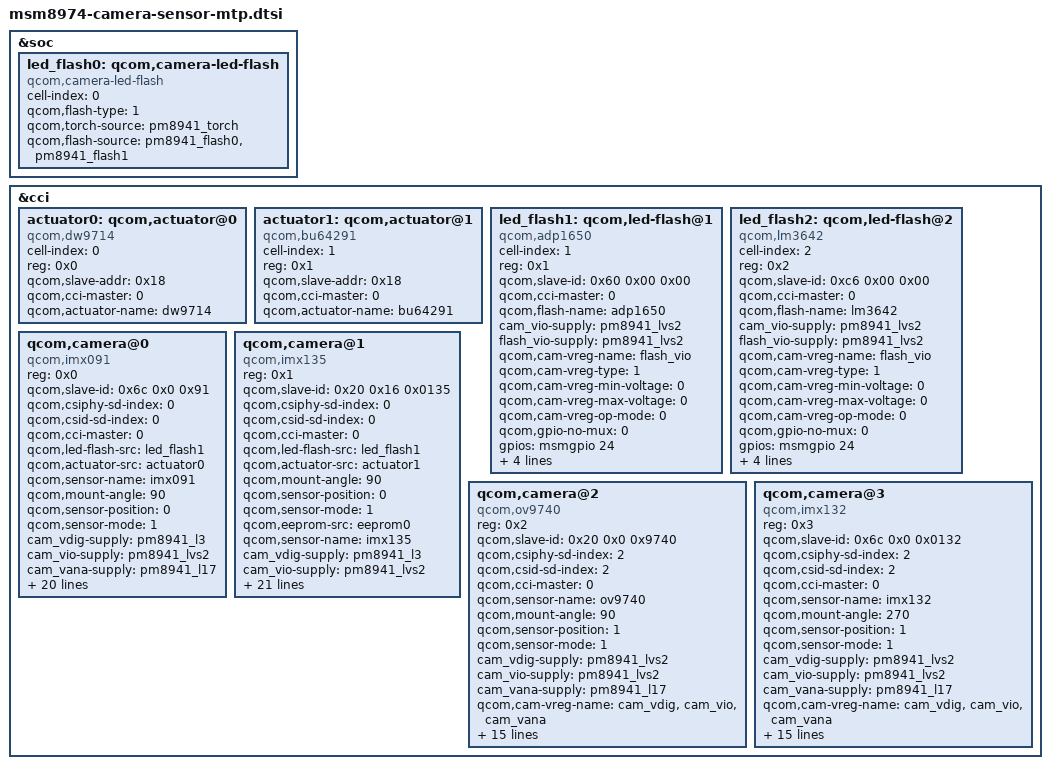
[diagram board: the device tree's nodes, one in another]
/*
 * Copyright (c) 2012-2013, The Linux Foundation. All rights reserved.
 *
 * This program is free software; you can redistribute it and/or modify
 * it under the terms of the GNU General Public License version 2 and
 * only version 2 as published by the Free Software Foundation.
 *
 * This program is distributed in the hope that it will be useful,
 * but WITHOUT ANY WARRANTY; without even the implied warranty of
 * MERCHANTABILITY or FITNESS FOR A PARTICULAR PURPOSE.  See the
 * GNU General Public License for more details.
 */

&soc {
	led_flash0: qcom,camera-led-flash {
		cell-index = <0>;
		compatible = "qcom,camera-led-flash";
		qcom,flash-type = <1>;
		qcom,torch-source = <&pm8941_torch>;
		qcom,flash-source = <&pm8941_flash0 &pm8941_flash1>;
	};
};

&cci {

/*
 * Commented by ZTE_JIA_20130419 jia.jia
 */
/*
	actuator0: qcom,actuator@18 {
		cell-index = <0>;
		reg = <0x18>;
		compatible = "qcom,actuator";
		qcom,cci-master = <0>;
	};

	actuator1: qcom,actuator@36 {
		cell-index = <1>;
		reg = <0x36>;
		compatible = "qcom,actuator";
		qcom,cci-master = <0>;
	};

	qcom,camera@6e {
		compatible = "qcom,s5k3l1yx";
		reg = <0x6e>;
		qcom,slave-id = <0x6e 0x0 0x3121>;
		qcom,csiphy-sd-index = <0>;
		qcom,csid-sd-index = <0>;
		qcom,actuator-src = <&actuator0>;
		qcom,led-flash-src = <&led_flash0>;
		qcom,mount-angle = <90>;
		qcom,sensor-name = "s5k3l1yx";
		cam_vdig-supply = <&pm8941_l3>;
		cam_vana-supply = <&pm8941_l17>;
		cam_vio-supply = <&pm8941_lvs3>;
		cam_vaf-supply = <&pm8941_l23>;
		qcom,cam-vreg-name = "cam_vdig", "cam_vio", "cam_vana",
				     "cam_vaf";
		qcom,cam-vreg-type = <0 1 0 0>;
		qcom,cam-vreg-min-voltage = <1225000 0 2850000 3000000>;
		qcom,cam-vreg-max-voltage = <1225000 0 2850000 3000000>;
		qcom,cam-vreg-op-mode = <105000 0 80000 100000>;
		qcom,gpio-no-mux = <0>;
		gpios = <&msmgpio 15 0>,
			<&msmgpio 90 0>,
			<&msmgpio 89 0>;
		qcom,gpio-reset = <1>;
		qcom,gpio-standby = <2>;
		qcom,gpio-req-tbl-num = <0 1 2>;
		qcom,gpio-req-tbl-flags = <1 0 0>;
		qcom,gpio-req-tbl-label = "CAMIF_MCLK",
					  "CAM_RESET1",
					  "CAM_STANDBY";
		qcom,gpio-set-tbl-num = <1 1>;
		qcom,gpio-set-tbl-flags = <0 2>;
		qcom,gpio-set-tbl-delay = <1000 30000>;
		qcom,csi-lane-assign = <0x4320>;
		qcom,csi-lane-mask = <0x1F>;
		qcom,sensor-position = <0>;
		qcom,sensor-mode = <1>;
		qcom,cci-master = <0>;
		status = "ok";
	};

    qcom,camera@20 {
		compatible = "qcom,imx135";
		reg = <0x20>;
		qcom,slave-id = <0x20 0x0016 0x0135>;
		qcom,csiphy-sd-index = <0>;
		qcom,csid-sd-index = <0>;
		qcom,mount-angle = <90>;
		qcom,sensor-name = "imx135";
		qcom,actuator-src = <&actuator1>;
		qcom,led-flash-src = <&led_flash0>;
		cam_vdig-supply = <&pm8941_l3>;
		cam_vana-supply = <&pm8941_l17>;
		cam_vio-supply = <&pm8941_lvs3>;
		cam_vaf-supply = <&pm8941_l23>;
		qcom,cam-vreg-name = "cam_vdig", "cam_vio", "cam_vana",
				     "cam_vaf";
		qcom,cam-vreg-type = <0 1 0 0>;
		qcom,cam-vreg-min-voltage = <1225000 0 2850000 3000000>;
		qcom,cam-vreg-max-voltage = <1225000 0 2850000 3000000>;
		qcom,cam-vreg-op-mode = <105000 0 80000 100000>;
		qcom,gpio-no-mux = <0>;
		gpios = <&msmgpio 15 0>,
			<&msmgpio 90 0>,
			<&msmgpio 89 0>;
		qcom,gpio-reset = <1>;
		qcom,gpio-standby = <2>;
		qcom,gpio-req-tbl-num = <0 1 2>;
		qcom,gpio-req-tbl-flags = <1 0 0>;
		qcom,gpio-req-tbl-label = "CAMIF_MCLK",
					  "CAM_RESET1",
					  "CAM_STANDBY";
		qcom,gpio-set-tbl-num = <1 1>;
		qcom,gpio-set-tbl-flags = <0 2>;
		qcom,gpio-set-tbl-delay = <1000 30000>;
		qcom,csi-lane-assign = <0x4320>;
		qcom,csi-lane-mask = <0x1F>;
		qcom,sensor-position = <0>;
		qcom,sensor-mode = <0>;
	        qcom,sensor-type = <0>;
		qcom,cci-master = <0>;
		status = "ok";
	};


	qcom,camera@6c {
		compatible = "qcom,ov2720";
		reg = <0x6c>;
		qcom,slave-id = <0x6c 0x300A 0x2720>;
		qcom,csiphy-sd-index = <2>;
		qcom,csid-sd-index = <2>;
		qcom,mount-angle = <90>;
		qcom,sensor-name = "ov2720";
		cam_vdig-supply = <&pm8941_l3>;
		cam_vana-supply = <&pm8941_l17>;
		cam_vio-supply = <&pm8941_lvs3>;
		qcom,cam-vreg-name = "cam_vdig", "cam_vana", "cam_vio";
		qcom,cam-vreg-type = <0 0 1>;
		qcom,cam-vreg-min-voltage = <1225000 2850000 0>;
		qcom,cam-vreg-max-voltage = <1225000 2850000 0>;
		qcom,cam-vreg-op-mode = <105000 80000 0>;
		qcom,gpio-no-mux = <0>;
		gpios = <&msmgpio 17 0>,
			<&msmgpio 18 0>;
		qcom,gpio-reset = <1>;
		qcom,gpio-req-tbl-num = <0 1>;
		qcom,gpio-req-tbl-flags = <1 0>;
		qcom,gpio-req-tbl-label = "CAMIF_MCLK",
					  "CAM_RESET1";
		qcom,gpio-set-tbl-num = <1 1>;
		qcom,gpio-set-tbl-flags = <0 2>;
		qcom,gpio-set-tbl-delay = <1000 4000>;
		qcom,csi-lane-assign = <0x4320>;
		qcom,csi-lane-mask = <0x7>;
		qcom,sensor-position = <1>;
		qcom,sensor-mode = <1>;
		qcom,cci-master = <1>;
		status = "ok";
	};

	qcom,camera@90 {
		compatible = "qcom,mt9m114";
		reg = <0x90>;
		qcom,slave-id = <0x90 0x0 0x2481>;
		qcom,csiphy-sd-index = <1>;
		qcom,csid-sd-index = <0>;
		qcom,mount-angle = <0>;
		qcom,sensor-name = "mt9m114";
		cam_vdig-supply = <&pm8941_l3>;
		cam_vana-supply = <&pm8941_l17>;
		cam_vio-supply = <&pm8941_lvs3>;
		qcom,cam-vreg-name = "cam_vdig", "cam_vana", "cam_vio";
		qcom,cam-vreg-type = <0 0 1>;
		qcom,cam-vreg-min-voltage = <1225000 2850000 0>;
		qcom,cam-vreg-max-voltage = <1225000 2850000 0>;
		qcom,cam-vreg-op-mode = <105000 80000 0>;
		qcom,gpio-no-mux = <0>;
		gpios = <&msmgpio 16 0>,
			<&msmgpio 92 0>;
		qcom,gpio-reset = <1>;
		qcom,gpio-req-tbl-num = <0 1>;
		qcom,gpio-req-tbl-flags = <1 0>;
		qcom,gpio-req-tbl-label = "CAMIF_MCLK",
					  "CAM_RESET1";
		qcom,gpio-set-tbl-num = <1 1>;
		qcom,gpio-set-tbl-flags = <0 2>;
		qcom,gpio-set-tbl-delay = <1000 4000>;
		qcom,csi-lane-assign = <0x4320>;
		qcom,csi-lane-mask = <0x3>;
		qcom,sensor-position = <1>;
		qcom,sensor-mode = <1>;
		qcom,cci-master = <0>;
	};
*/

/*
 * Common configuration of camera sensor & flash by ZTE_JIA_20130925, jia.jia
 *
 * See: arch/arm/boot/dts/msm8974-camera.dtsi
 *      arch/arm/boot/dts/msm8974-camera-sensor-mtp.dtsi
 *      arch/arm/boot/dts/msm8974-camera-sensor-mtp-avon.dtsi
 *      arch/arm/boot/dts/msm8974pro-ab-camera-sensor-mtp-barron.dtsi
 *      arch/arm/boot/dts/msm8974pro-ac-camera-sensor-mtp-barron.dtsi
 *      arch/arm/boot/dts/msm8974pro-ab-camera-sensor-mtp-chovar.dtsi
 */
// --->
	/*
	 * Support for Dongwoon dw9714
	 */
	actuator0: qcom,actuator@0 {
		cell-index = <0>;
		reg = <0x0>;
		qcom,slave-addr = <0x18>;
		compatible = "qcom,dw9714";
		qcom,cci-master = <0>;
		qcom,actuator-name = "dw9714";
	};

	/*
	 * Support for Rohm bu64291
	 */
	actuator1: qcom,actuator@1 {
		cell-index = <1>;
		reg = <0x1>;
		qcom,slave-addr = <0x18>;
		compatible = "qcom,bu64291";
		qcom,cci-master = <0>;
		qcom,actuator-name = "bu64291";
	};

	/*
	 * Support for AD adp1650
	 */
	led_flash1: qcom,led-flash@1 {
		cell-index = <1>;
		reg = <0x1>;
		qcom,slave-id = <0x60 0x00 0x00>;
		compatible = "qcom,adp1650";
		qcom,cci-master = <0>;
		qcom,flash-name = "adp1650";

		/*
		 * VDD configuration
		 *
		 * Refer to: kernel/include/media/msm_cam_sensor.h
		 * enum msm_camera_vreg_name_t {
		 *   CAM_VDIG,
		 *   CAM_VIO,
		 *   CAM_VANA,
		 *   CAM_VAF,
		 *   CAM_VREG_MAX,
		 * };
		 * Attention: index of qcom,cam-vreg-* MUST be as same as that of 'msm_camera_vreg_name_t'
		 *
		 * enum camera_vreg_type {
		 *   REG_LDO,
		 *   REG_VS,
		 *   REG_GPIO,
		 * };
		 * Attention: 'min-voltage'/'max-voltage'/'op-mode' only required by ''REG_LDO'
		 */
		cam_vio-supply = <&pm8941_lvs2>;
		flash_vio-supply = <&pm8941_lvs2>;
		qcom,cam-vreg-name = "flash_vio";
		qcom,cam-vreg-type = <1>;
		qcom,cam-vreg-min-voltage = <0>;
		qcom,cam-vreg-max-voltage = <0>;
		qcom,cam-vreg-op-mode = <0>;

		/*
		 * GPIO configuration
		 */
		qcom,gpio-no-mux = <0>;
		gpios = <&msmgpio 24 0>;
		qcom,gpio-strobe = <0>;
		qcom,gpio-req-tbl-num = <0>;

		/* 0: output gpio, 1: input gpio */
		qcom,gpio-req-tbl-flags = <0>;

		qcom,gpio-req-tbl-label = "FLASH_STROBE";

		status = "ok";
	};

	/*
	 * Support for TI lm3642
	 */
	led_flash2: qcom,led-flash@2 {
		cell-index = <2>;
		reg = <0x2>;
		qcom,slave-id = <0xc6 0x00 0x00>;
		compatible = "qcom,lm3642";
		qcom,cci-master = <0>;
		qcom,flash-name = "lm3642";

		/*
		 * VDD configuration
		 *
		 * Refer to: kernel/include/media/msm_cam_sensor.h
		 * enum msm_camera_vreg_name_t {
		 *   CAM_VDIG,
		 *   CAM_VIO,
		 *   CAM_VANA,
		 *   CAM_VAF,
		 *   CAM_VREG_MAX,
		 * };
		 * Attention: index of qcom,cam-vreg-* MUST be as same as that of 'msm_camera_vreg_name_t'
		 *
		 * enum camera_vreg_type {
		 *   REG_LDO,
		 *   REG_VS,
		 *   REG_GPIO,
		 * };
		 * Attention: 'min-voltage'/'max-voltage'/'op-mode' only required by ''REG_LDO'
		 */
		cam_vio-supply = <&pm8941_lvs2>;
		flash_vio-supply = <&pm8941_lvs2>;
		qcom,cam-vreg-name = "flash_vio";
		qcom,cam-vreg-type = <1>;
		qcom,cam-vreg-min-voltage = <0>;
		qcom,cam-vreg-max-voltage = <0>;
		qcom,cam-vreg-op-mode = <0>;

		/*
		 * GPIO configuration
		 */
		qcom,gpio-no-mux = <0>;
		gpios = <&msmgpio 24 0>;
		qcom,gpio-strobe = <0>;
		qcom,gpio-req-tbl-num = <0>;

		/* 0: output gpio, 1: input gpio */
		qcom,gpio-req-tbl-flags = <0>;

		qcom,gpio-req-tbl-label = "FLASH_STROBE";

		status = "ok";
	};

	/*
	 * Support for Sony imx091 13Mp
	 *
	 * 'qcom,camera@X' & 'reg = <0xX>': index of camera sensor for mclk
	 * refer to kernel/arch/arm/mach-msm/clock-8974.c
	 *
	 * 'qcom,csid-sd-index' should be set as same as 'qcom,csiphy-sd-index'
	 * for rear/front camera, otherwise 'csid_open' will return error.
	 */
	qcom,camera@0 {
		compatible = "qcom,imx091";
		reg = <0x0>;
		qcom,slave-id = <0x6c 0x0 0x91>;
		qcom,csiphy-sd-index = <0>;
		qcom,csid-sd-index = <0>;
		qcom,cci-master = <0>;
		qcom,led-flash-src = <&led_flash1>;
		qcom,actuator-src = <&actuator0>;
		qcom,sensor-name = "imx091";

		/*
		 * Refer to:
		 *
		 * enum camb_position_t {
		 *   BACK_CAMERA_B,
		 *   FRONT_CAMERA_B,
		 * };
		 *
		 * enum camerab_mode_t {
		 *   CAMERA_MODE_2D_B = (1<<0),
		 *   CAMERA_MODE_3D_B = (1<<1)
		 * };
		 */
		qcom,mount-angle = <90>;
		qcom,sensor-position = <0>;
		qcom,sensor-mode = <1>;

		/*
		 * Check calibration process in mm-camera required
		 * Disabled here
		 */
		//qcom,eeprom-src = <&eeprom0>;

		/*
		 * VDD configuration
		 *
		 * Refer to: kernel/include/media/msm_cam_sensor.h
		 * enum msm_camera_vreg_name_t {
		 *   CAM_VDIG,
		 *   CAM_VIO,
		 *   CAM_VANA,
		 *   CAM_VAF,
		 *   CAM_VREG_MAX,
		 * };
		 * Attention: index of qcom,cam-vreg-* MUST be as same as that of 'msm_camera_vreg_name_t'
		 *
		 * enum camera_vreg_type {
		 *   REG_LDO,
		 *   REG_VS,
		 *   REG_GPIO,
		 * };
		 * Attention: 'min-voltage'/'max-voltage'/'op-mode' only required by ''REG_LDO'
		 */
		cam_vdig-supply = <&pm8941_l3>;
		cam_vio-supply = <&pm8941_lvs2>;
		cam_vana-supply = <&pm8941_l17>;
		cam_vaf-supply = <&pm8941_l23>;
		qcom,cam-vreg-name = "cam_vdig", "cam_vio", "cam_vana", "cam_vaf";
		qcom,cam-vreg-type = <0 1 0 0>;
		qcom,cam-vreg-min-voltage = <1225000 0 2850000 2850000>;
		qcom,cam-vreg-max-voltage = <1225000 0 2850000 2850000>;
		qcom,cam-vreg-op-mode = <105000 0 80000 80000>;

		/*
		 * GPIO configuration
		 */
		qcom,gpio-no-mux = <0>;
		gpios = <&msmgpio 15 0>, <&msmgpio 89 0>, <&msmgpio 90 0>;
		qcom,gpio-req-tbl-num = <0 1 2>;

		/* 0: output gpio, 1: input gpio */
		qcom,gpio-req-tbl-flags = <1 0 0>;

		qcom,gpio-req-tbl-label = "CAM0_MCLK", "CAM0_STANDBY", "CAM0_RESET";

		/*
		 * Disused here
		 * refer to: kernel/drivers/media/platform/msm/camera_v2/sensor/imx091.c
		 */
		qcom,gpio-set-tbl-num = <0>;

		/* 0: GPIOF_OUT_INIT_LOW, 2: GPIOF_OUT_INIT_HIGH */
		qcom,gpio-set-tbl-flags = <0>;

		qcom,gpio-set-tbl-delay = <0>;

		/*
		 * 'qcom,csi-lane-mask' specifies CSIPHY lanes to be enabled
		 * 4 lane : 0x1F
		 * 2 lane : 0x7
		 * 1 lane : 0x3
		 *
		 * 'qcom,csi-lane-mask = 0x1F = 0b00011111' refered to 5 pairs of CSI ports on PCB layout, i.e.,
		 *
		 * MIPI_CSI2_LN0_N / MIPI_CSI2_LN0_P
		 * MIPI_CSI2_LN1_N|MIPI_CSI2_CLK_N / MIPI_CSI2_LN1_P|MIPI_CSI2_CLK_P
		 * MIPI_CSI2_LN2_N / MIPI_CSI2_LN2_P
		 * MIPI_CSI2_LN3_N / MIPI_CSI2_LN3_P
		 * MIPI_CSI2_LN4_N / MIPI_CSI2_LN4_P
		 */
		qcom,csi-lane-assign = <0x4320>;
		qcom,csi-lane-mask = <0x1F>;

		status = "ok";
	};

	/*
	 * Support for Sony imx135 13Mp
	 *
	 * 'qcom,camera@X' & 'reg = <0xX>': index of camera sensor for mclk
	 * refer to kernel/arch/arm/mach-msm/clock-8974.c
	 *
	 * 'qcom,csid-sd-index' should be set as same as 'qcom,csiphy-sd-index'
	 * for rear/front camera, otherwise 'csid_open' will return error.
	 */
	qcom,camera@1 {
		compatible = "qcom,imx135";
		reg = <0x1>;
		qcom,slave-id = <0x20 0x16 0x0135>;
		qcom,csiphy-sd-index = <0>;
		qcom,csid-sd-index = <0>;
		qcom,cci-master = <0>;
		qcom,led-flash-src = <&led_flash1>;
		qcom,actuator-src = <&actuator1>;

		/*
		 * Refer to:
		 *
		 * enum camb_position_t {
		 *   BACK_CAMERA_B,
		 *   FRONT_CAMERA_B,
		 * };
		 *
		 * enum camerab_mode_t {
		 *   CAMERA_MODE_2D_B = (1<<0),
		 *   CAMERA_MODE_3D_B = (1<<1)
		 * };
		 */
		qcom,mount-angle = <90>;
		qcom,sensor-position = <0>;
		qcom,sensor-mode = <1>;

		/*
		 * Check calibration process in mm-camera required
		 */
		qcom,eeprom-src = <&eeprom0>;

		qcom,sensor-name = "imx135";

		/*
		 * VDD configuration
		 *
		 * Refer to: kernel/include/media/msm_cam_sensor.h
		 * enum msm_camera_vreg_name_t {
		 *   CAM_VDIG,
		 *   CAM_VIO,
		 *   CAM_VANA,
		 *   CAM_VAF,
		 *   CAM_VREG_MAX,
		 * };
		 * Attention: index of qcom,cam-vreg-* MUST be as same as that of 'msm_camera_vreg_name_t'
		 *
		 * enum camera_vreg_type {
		 *   REG_LDO,
		 *   REG_VS,
		 *   REG_GPIO,
		 * };
		 * Attention: 'min-voltage'/'max-voltage'/'op-mode' only required by ''REG_LDO'
		 */
		cam_vdig-supply = <&pm8941_l3>;
		cam_vio-supply = <&pm8941_lvs2>;
		cam_vana-supply = <&pm8941_l17>;
		cam_vaf-supply = <&pm8941_l23>;
		qcom,cam-vreg-name = "cam_vdig", "cam_vio", "cam_vana", "cam_vaf";
		qcom,cam-vreg-type = <0 1 0 0>;
		qcom,cam-vreg-min-voltage = <1050000 0 2850000 2850000>;
		qcom,cam-vreg-max-voltage = <1050000 0 2850000 2850000>;
		qcom,cam-vreg-op-mode = <105000 0 80000 80000>;

		/*
		 * GPIO configuration
		 */
		qcom,gpio-no-mux = <0>;
		gpios = <&msmgpio 15 0>, <&msmgpio 89 0>, <&msmgpio 90 0>;
		qcom,gpio-req-tbl-num = <0 1 2>;

		/* 0: output gpio, 1: input gpio */
		qcom,gpio-req-tbl-flags = <1 0 0>;

		qcom,gpio-req-tbl-label = "CAM0_MCLK", "CAM0_STANDBY", "CAM0_RESET";

		/*
		 * Disused here
		 * refer to: kernel/drivers/media/platform/msm/camera_v2/sensor/imx135.c
		 */
		qcom,gpio-set-tbl-num = <0>;

		/* 0: GPIOF_OUT_INIT_LOW, 2: GPIOF_OUT_INIT_HIGH */
		qcom,gpio-set-tbl-flags = <0>;

		qcom,gpio-set-tbl-delay = <0>;

		/*
		 * 'qcom,csi-lane-mask' specifies CSIPHY lanes to be enabled
		 * 4 lane : 0x1F
		 * 2 lane : 0x7
		 * 1 lane : 0x3
		 *
		 * 'qcom,csi-lane-mask = 0x1F = 0b00011111' refered to 5 pairs of CSI ports on PCB layout, i.e.,
		 *
		 * MIPI_CSI2_LN0_N / MIPI_CSI2_LN0_P
		 * MIPI_CSI2_LN1_N|MIPI_CSI2_CLK_N / MIPI_CSI2_LN1_P|MIPI_CSI2_CLK_P
		 * MIPI_CSI2_LN2_N / MIPI_CSI2_LN2_P
		 * MIPI_CSI2_LN3_N / MIPI_CSI2_LN3_P
		 * MIPI_CSI2_LN4_N / MIPI_CSI2_LN4_P
		 */
		qcom,csi-lane-assign = <0x4320>;
		qcom,csi-lane-mask = <0x1F>;

		status = "ok";
	};

	/*
	 * Support for OV ov9740 720p
	 *
	 * 'qcom,camera@X' & 'reg = <0xX>': index of camera sensor for mclk
	 * refer to kernel/arch/arm/mach-msm/clock-8974.c
	 *
	 * 'qcom,csid-sd-index' should be set as same as 'qcom,csiphy-sd-index'
	 * for rear/front camera, otherwise 'csid_open' will return error.
	 */
	qcom,camera@2 {
		compatible = "qcom,ov9740";
		reg = <0x2>;
		qcom,slave-id = <0x20 0x0 0x9740>;
		qcom,csiphy-sd-index = <2>;
		qcom,csid-sd-index = <2>;
		qcom,cci-master = <0>;
		qcom,sensor-name = "ov9740";

		/*
		 * Refer to:
		 *
		 * enum camb_position_t {
		 *   BACK_CAMERA_B,
		 *   FRONT_CAMERA_B,
		 * };
		 *
		 * enum camerab_mode_t {
		 *   CAMERA_MODE_2D_B = (1<<0),
		 *   CAMERA_MODE_3D_B = (1<<1)
		 * };
		 */
		qcom,mount-angle = <90>;
		qcom,sensor-position = <1>;
		qcom,sensor-mode = <1>;

		/*
		 * VDD configuration
		 *
		 * Refer to: kernel/include/media/msm_cam_sensor.h
		 * enum msm_camera_vreg_name_t {
		 *   CAM_VDIG,
		 *   CAM_VIO,
		 *   CAM_VANA,
		 *   CAM_VAF,
		 *   CAM_VREG_MAX,
		 * };
		 * Attention: index of qcom,cam-vreg-* MUST be as same as that of 'msm_camera_vreg_name_t'
		 *
		 * enum camera_vreg_type {
		 *   REG_LDO,
		 *   REG_VS,
		 *   REG_GPIO,
		 * };
		 * Attention: 'min-voltage'/'max-voltage'/'op-mode' only required by ''REG_LDO'
		 */
		cam_vdig-supply = <&pm8941_lvs2>;
		cam_vio-supply = <&pm8941_lvs2>;
		cam_vana-supply = <&pm8941_l17>;
		qcom,cam-vreg-name = "cam_vdig", "cam_vio", "cam_vana";
		qcom,cam-vreg-type = <1 1 0>;
		qcom,cam-vreg-min-voltage = <0 0 2850000>;
		qcom,cam-vreg-max-voltage = <0 0 2850000>;
		qcom,cam-vreg-op-mode = <0 0 80000>;

		/*
		 * GPIO configuration
		 */
		qcom,gpio-no-mux = <0>;
		gpios = <&msmgpio 17 0>, <&msmgpio 91 0>, <&msmgpio 92 0>;
		qcom,gpio-req-tbl-num = <0 1 2>;

		/* 0: output gpio, 1: input gpio */
		qcom,gpio-req-tbl-flags = <1 0 0>;

		qcom,gpio-req-tbl-label = "CAM1_MCLK", "CAM1_STANDBY", "CAM1_RESET";

		/*
		 * Disused here
		 * refer to: kernel/drivers/media/platform/msm/camera_v2/sensor/ov9740.c
		 */
		qcom,gpio-set-tbl-num = <0>;

		/* 0: GPIOF_OUT_INIT_LOW, 2: GPIOF_OUT_INIT_HIGH */
		qcom,gpio-set-tbl-flags = <0>;

		qcom,gpio-set-tbl-delay = <0>;

		/*
		 * 'qcom,csi-lane-mask' specifies CSIPHY lanes to be enabled
		 * 4 lane : 0x1F
		 * 2 lane : 0x7
		 * 1 lane : 0x3
		 *
		 * 'qcom,csi-lane-mask = 0x3 = 0b0011' refered to 2 pairs of CSI ports on PCB layout, i.e.,
		 *
		 * MIPI_CSI2_LN0_N / MIPI_CSI2_LN0_P
		 * MIPI_CSI2_LN1_N|MIPI_CSI2_CLK_N / MIPI_CSI2_LN1_P|MIPI_CSI2_CLK_P
		 */
		qcom,csi-lane-assign = <0x4320>;
		qcom,csi-lane-mask = <0x3>;

		status = "ok";
	};

	/*
	 * Support for Sony imx132 2.4Mp
	 *
	 * 'qcom,camera@X' & 'reg = <0xX>': index of camera sensor for mclk
	 * refer to kernel/arch/arm/mach-msm/clock-8974.c
	 *
	 * 'qcom,csid-sd-index' should be set as same as 'qcom,csiphy-sd-index'
	 * for rear/front camera, otherwise 'csid_open' will return error.
	 */
	qcom,camera@3 {
		compatible = "qcom,imx132";
		reg = <0x3>;
		qcom,slave-id = <0x6c 0x0 0x0132>;
		qcom,csiphy-sd-index = <2>;
		qcom,csid-sd-index = <2>;
		qcom,cci-master = <0>;
		qcom,sensor-name = "imx132";

		/*
		 * Refer to:
		 *
		 * enum camb_position_t {
		 *   BACK_CAMERA_B,
		 *   FRONT_CAMERA_B,
		 * };
		 *
		 * enum camerab_mode_t {
		 *   CAMERA_MODE_2D_B = (1<<0),
		 *   CAMERA_MODE_3D_B = (1<<1)
		 * };
		 */
		 /*
		 * Refer to:
		 *
		 * preview rotation: '{ 0x0101, 0x00 }' in mm-camera2 of vendor
		 *                   'V4L2_PIX_FMT_SRGGB10' in mm-camera2 of vendor
		 *
		 * snapshot rotation: 'qcom,mount-angle = <90>' in kernel
		 *                    'V4L2_PIX_FMT_SRGGB10' in mm-camera2 of vendor
		 */
		/*
		 * Correct clockwise rotation with 180 degree for snapshot
		 */
		// qcom,mount-angle = <90>;
		qcom,mount-angle = <270>;
		qcom,sensor-position = <1>;
		qcom,sensor-mode = <1>;

		/*
		 * VDD configuration
		 *
		 * Refer to: kernel/include/media/msm_cam_sensor.h
		 * enum msm_camera_vreg_name_t {
		 *   CAM_VDIG,
		 *   CAM_VIO,
		 *   CAM_VANA,
		 *   CAM_VAF,
		 *   CAM_VREG_MAX,
		 * };
		 * Attention: index of qcom,cam-vreg-* MUST be as same as that of 'msm_camera_vreg_name_t'
		 *
		 * enum camera_vreg_type {
		 *   REG_LDO,
		 *   REG_VS,
		 *   REG_GPIO,
		 * };
		 * Attention: 'min-voltage'/'max-voltage'/'op-mode' only required by ''REG_LDO'
		 */
		cam_vdig-supply = <&pm8941_lvs2>;
		cam_vio-supply = <&pm8941_lvs2>;
		cam_vana-supply = <&pm8941_l17>;
		qcom,cam-vreg-name = "cam_vdig", "cam_vio", "cam_vana";
		qcom,cam-vreg-type = <1 1 0>;
		qcom,cam-vreg-min-voltage = <0 0 2850000>;
		qcom,cam-vreg-max-voltage = <0 0 2850000>;
		qcom,cam-vreg-op-mode = <0 0 80000>;

		/*
		 * GPIO configuration
		 */
		qcom,gpio-no-mux = <0>;
		gpios = <&msmgpio 17 0>, <&msmgpio 91 0>, <&msmgpio 92 0>;
		qcom,gpio-req-tbl-num = <0 1 2>;

		/* 0: output gpio, 1: input gpio */
		qcom,gpio-req-tbl-flags = <1 0 0>;

		qcom,gpio-req-tbl-label = "CAM1_MCLK", "CAM1_STANDBY", "CAM1_RESET";

		/*
		 * Disused here
		 * refer to: kernel/drivers/media/platform/msm/camera_v2/sensor/imx132.c
		 */
		qcom,gpio-set-tbl-num = <0>;

		/* 0: GPIOF_OUT_INIT_LOW, 2: GPIOF_OUT_INIT_HIGH */
		qcom,gpio-set-tbl-flags = <0>;

		qcom,gpio-set-tbl-delay = <0>;

		/*
		 * 'qcom,csi-lane-mask' specifies CSIPHY lanes to be enabled
		 * 4 lane : 0x1F
		 * 2 lane : 0x7
		 * 1 lane : 0x3
		 *
		 * 'qcom,csi-lane-mask = 0x7 = 0b0111' refered to 3 pairs of CSI ports on PCB layout, i.e.,
		 *
		 * MIPI_CSI2_LN0_N / MIPI_CSI2_LN0_P
		 * MIPI_CSI2_LN1_N|MIPI_CSI2_CLK_N / MIPI_CSI2_LN1_P|MIPI_CSI2_CLK_P
		 * MIPI_CSI2_LN2_N / MIPI_CSI2_LN2_P
		 */
		qcom,csi-lane-assign = <0x4320>;
		qcom,csi-lane-mask = <0x7>;

		status = "ok";
	};
// <---
};
